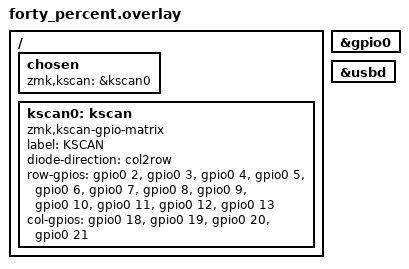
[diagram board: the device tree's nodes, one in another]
/*
 * Copyright (c) 2020 Pete Johanson, Ryan Cross
 *
 * SPDX-License-Identifier: MIT
 */

#include <dt-bindings/zmk/matrix_transform.h>

/ {
    chosen {
        zmk,kscan = &kscan0;
    };

    kscan0: kscan {
        compatible = "zmk,kscan-gpio-matrix";
        label = "KSCAN";

        diode-direction = "col2row";
        row-gpios
            = <&gpio0 2 (GPIO_ACTIVE_HIGH | GPIO_PULL_DOWN)>
            , <&gpio0 3 (GPIO_ACTIVE_HIGH | GPIO_PULL_DOWN)>
            , <&gpio0 4 (GPIO_ACTIVE_HIGH | GPIO_PULL_DOWN)>
            , <&gpio0 5 (GPIO_ACTIVE_HIGH | GPIO_PULL_DOWN)>
            , <&gpio0 6 (GPIO_ACTIVE_HIGH | GPIO_PULL_DOWN)>
            , <&gpio0 7 (GPIO_ACTIVE_HIGH | GPIO_PULL_DOWN)>
            , <&gpio0 8 (GPIO_ACTIVE_HIGH | GPIO_PULL_DOWN)>
            , <&gpio0 9 (GPIO_ACTIVE_HIGH | GPIO_PULL_DOWN)>
            , <&gpio0 10 (GPIO_ACTIVE_HIGH | GPIO_PULL_DOWN)>
            , <&gpio0 11 (GPIO_ACTIVE_HIGH | GPIO_PULL_DOWN)>
            , <&gpio0 12 (GPIO_ACTIVE_HIGH | GPIO_PULL_DOWN)>
            , <&gpio0 13 (GPIO_ACTIVE_HIGH | GPIO_PULL_DOWN)>
            ;
	      col-gpios
            = <&gpio0 18 GPIO_ACTIVE_HIGH>
            , <&gpio0 19 GPIO_ACTIVE_HIGH>
		        , <&gpio0 20 GPIO_ACTIVE_HIGH>
		        , <&gpio0 21 GPIO_ACTIVE_HIGH>
		        ;
    };
};

&gpio0 {
    status = "okay";
};

&usbd {
    status = "okay";
};
